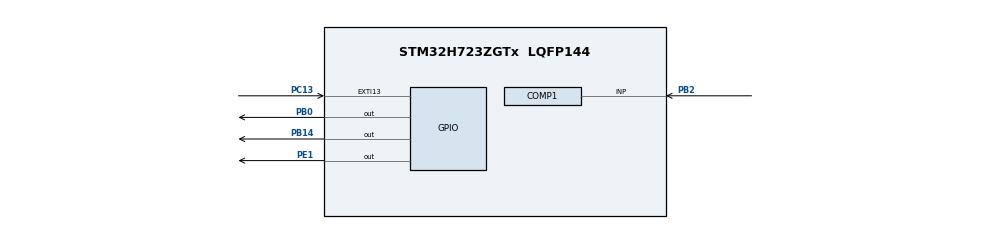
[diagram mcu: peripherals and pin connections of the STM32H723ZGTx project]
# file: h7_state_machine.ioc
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Mcu.Family=STM32H7
Mcu.Name=STM32H723ZGTx
Mcu.Package=LQFP144
NVIC.EXTI15_10_IRQn=true\:0\:0\:false\:false\:true\:true\:true
NVIC.PriorityGroup=NVIC_PRIORITYGROUP_4
PA13(JTMS/SWDIO).Mode=Serial_Wire
PA13(JTMS/SWDIO).Signal=DEBUG_JTMS-SWDIO
PA14(JTCK/SWCLK).Mode=Serial_Wire
PA14(JTCK/SWCLK).Signal=DEBUG_JTCK-SWCLK
PB0.Signal=GPIO_Output
PB14.Signal=GPIO_Output
PB2.Mode=INP
PB2.Signal=COMP1_INP
PC13.Signal=GPXTI13
PE1.Signal=GPIO_Output
ProjectManager.HeapSize=0x200
ProjectManager.StackSize=0x400
ProjectManager.TargetToolchain=STM32CubeIDE
RCC.ADCFreq_Value=129000000
RCC.APB1Freq_Value=32000000
RCC.APB2Freq_Value=32000000
RCC.APB3Freq_Value=32000000
RCC.APB4Freq_Value=32000000
RCC.CortexFreq_Value=64000000
RCC.D1PPRE=RCC_APB3_DIV2
RCC.D2PPRE1=RCC_APB1_DIV2
RCC.D2PPRE2=RCC_APB2_DIV2
RCC.D3PPRE=RCC_APB4_DIV2
RCC.HCLKFreq_Value=64000000
RCC.SYSCLKFreq_VALUE=64000000
RCC.USBFreq_Value=129000000
VP_COMP1_VS_VREFINT.Mode=VREFINT
board=custom

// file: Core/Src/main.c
/* USER CODE BEGIN Header */
/**
  ******************************************************************************
  * @file           : main.c
  * @brief          : Main program body
  ******************************************************************************
  * @attention
  *
  * <h2><center>&copy; Copyright (c) 2021 STMicroelectronics.
  * All rights reserved.</center></h2>
  *
  * This software component is licensed by ST under BSD 3-Clause license,
  * the "License"; You may not use this file except in compliance with the
  * License. You may obtain a copy of the License at:
  *                        opensource.org/licenses/BSD-3-Clause
  *
  ******************************************************************************
  */
/* USER CODE END Header */
#include "main.h"
#include "comp.h"
#include "gpio.h"

/* USER CODE BEGIN Includes */
#include "msg.h"
#include "app.h"
/* USER CODE END Includes */

void SystemClock_Config(void);

int main(void)
{

  /* MCU Configuration--------------------------------------------------------*/

  /* Reset of all peripherals, Initializes the Flash interface and the Systick. */
  HAL_Init();

  /* Configure the system clock */
  SystemClock_Config();

  /* Initialize all configured peripherals */
  MX_GPIO_Init();
  MX_COMP1_Init();
  /* USER CODE BEGIN 2 */
  app_first_init();
  app_second_init();
  app_third_init();
  app_start_app(APP_first);
  /* USER CODE END 2 */

  /* Infinite loop */
  /* USER CODE BEGIN WHILE */
  while (1)
  {
    app_process();
    /* USER CODE END WHILE */

  }
}

void SystemClock_Config(void)
{
  RCC_OscInitTypeDef RCC_OscInitStruct = {0};
  RCC_ClkInitTypeDef RCC_ClkInitStruct = {0};

  /** Supply configuration update enable
  */
  HAL_PWREx_ConfigSupply(PWR_LDO_SUPPLY);
  /** Configure the main internal regulator output voltage
  */
  __HAL_PWR_VOLTAGESCALING_CONFIG(PWR_REGULATOR_VOLTAGE_SCALE3);

  while(!__HAL_PWR_GET_FLAG(PWR_FLAG_VOSRDY)) {}
  /** Initializes the RCC Oscillators according to the specified parameters
  * in the RCC_OscInitTypeDef structure.
  */
  RCC_OscInitStruct.OscillatorType = RCC_OSCILLATORTYPE_HSI;
  RCC_OscInitStruct.HSIState = RCC_HSI_DIV1;
  RCC_OscInitStruct.HSICalibrationValue = RCC_HSICALIBRATION_DEFAULT;
  RCC_OscInitStruct.PLL.PLLState = RCC_PLL_NONE;
  if (HAL_RCC_OscConfig(&RCC_OscInitStruct) != HAL_OK)
  {
    Error_Handler();
  }
  /** Initializes the CPU, AHB and APB buses clocks
  */
  RCC_ClkInitStruct.ClockType = RCC_CLOCKTYPE_HCLK|RCC_CLOCKTYPE_SYSCLK
                              |RCC_CLOCKTYPE_PCLK1|RCC_CLOCKTYPE_PCLK2
                              |RCC_CLOCKTYPE_D3PCLK1|RCC_CLOCKTYPE_D1PCLK1;
  RCC_ClkInitStruct.SYSCLKSource = RCC_SYSCLKSOURCE_HSI;
  RCC_ClkInitStruct.SYSCLKDivider = RCC_SYSCLK_DIV1;
  RCC_ClkInitStruct.AHBCLKDivider = RCC_HCLK_DIV1;
  RCC_ClkInitStruct.APB3CLKDivider = RCC_APB3_DIV2;
  RCC_ClkInitStruct.APB1CLKDivider = RCC_APB1_DIV2;
  RCC_ClkInitStruct.APB2CLKDivider = RCC_APB2_DIV2;
  RCC_ClkInitStruct.APB4CLKDivider = RCC_APB4_DIV2;

  if (HAL_RCC_ClockConfig(&RCC_ClkInitStruct, FLASH_LATENCY_1) != HAL_OK)
  {
    Error_Handler();
  }
}

/* USER CODE BEGIN 4 */
void HAL_GPIO_EXTI_Callback(uint16_t GPIO_Pin)
{
  if(GPIO_Pin == GPIO_PIN_13)
  {
    app_set_msg(MSG_KEY_INTERRUPT, 0, 0);
  }
}
/* USER CODE END 4 */

void Error_Handler(void)
{
  __disable_irq();
  while (1)
  {
  }
}

/************************ (C) COPYRIGHT STMicroelectronics *****END OF FILE****/
